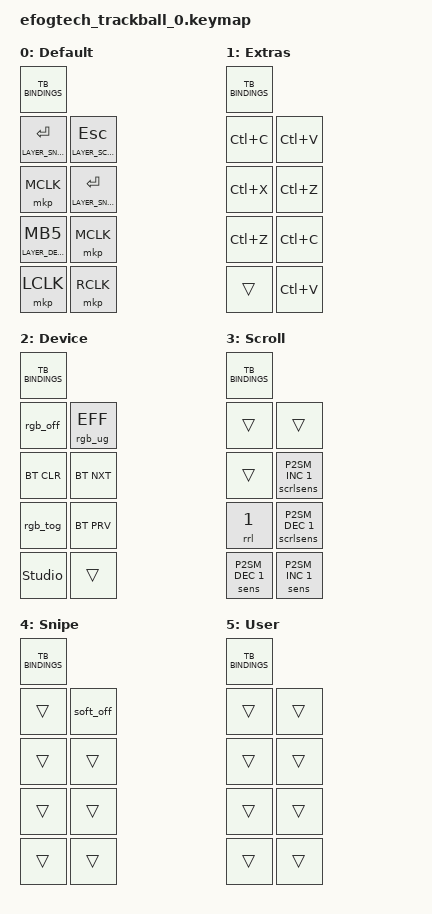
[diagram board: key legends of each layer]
#define ZMK_POINTING_DEFAULT_SCRL_VAL 30 /* faster default scroll speed */
#include <behaviors.dtsi>
#include <dt-bindings/zmk/bt.h>
#include <dt-bindings/zmk/keys.h>
#include <dt-bindings/zmk/pointing.h>
#include <dt-bindings/zmk/outputs.h>
#include <dt-bindings/zmk/p2sm.h>
#include <dt-bindings/zmk/rgb.h>
#include <dt-bindings/zmk/ext_power.h>
#include <behaviors/p2sm_behaviors.dtsi>
#include <behaviors/rate_limit.dtsi>
#include <behaviors/auto_hold.dtsi>

#ifndef CONFIG_EFOG_SCROLL_STEP
#define CONFIG_EFOG_SCROLL_STEP 10
#endif
#ifndef CONFIG_EFOG_SCROLL_MIN_STEP
#define CONFIG_EFOG_SCROLL_MIN_STEP 2
#endif
#ifndef CONFIG_EFOG_SCROLL_MAX_STEP
#define CONFIG_EFOG_SCROLL_MAX_STEP 12
#endif
#ifndef CONFIG_EFOG_SCROLL_TOGGLE_STEP
#define CONFIG_EFOG_SCROLL_TOGGLE_STEP 30
#endif
#ifndef CONFIG_EFOG_SCROLL_TOGGLE_MIN
#define CONFIG_EFOG_SCROLL_TOGGLE_MIN 1
#endif
#ifndef CONFIG_EFOG_SCROLL_TOGGLE_MAX
#define CONFIG_EFOG_SCROLL_TOGGLE_MAX 2
#endif

#define LAYER_DEFAULT 0
#define LAYER_EXTRAS 1
#define LAYER_DEVICE 2
#define LAYER_SCROLL 3
#define LAYER_SNIPE 4
#define LAYER_USER 5

#define SCROLL_MULTIPLIER 1
#define SCROLL_DIVISOR 3

#define SNIPE_MULTIPLIER 1
#define SNIPE_DIVISOR 4

#ifdef CONFIG_EFOG_TRACKBALL_POINTER_FLIPPED
/* Rotate the 2x4 key matrix when the board is mounted upside down. */
#define TB_BINDINGS( \
		r0c0, r0c1, \
		r1c0, r1c1, \
		r2c0, r2c1, \
		r3c0, r3c1) \
	r3c1 r3c0 \
	r2c1 r2c0 \
	r1c1 r1c0 \
	r0c1 r0c0
#else
#define TB_BINDINGS( \
		r0c0, r0c1, \
		r1c0, r1c1, \
		r2c0, r2c1, \
		r3c0, r3c1) \
	r0c0 r0c1 \
	r1c0 r1c1 \
	r2c0 r2c1 \
	r3c0 r3c1
#endif

/ {
	keymap {
		compatible = "zmk,keymap";

		default_layer {
			display-name = "Default";
			sensor-bindings = <&inc_dec_kp C_VOL_DN C_VOL_UP &inc_dec_kp LC(TAB) LC(LS(TAB))>;
			bindings = <
				TB_BINDINGS(
					&ltmkp LAYER_SNIPE ENTER,  &ltmkp LAYER_SCROLL ESC,
					&mkp MCLK,                &ltmkp LAYER_SNIPE ENTER,
					&ltm LAYER_DEVICE MB5,    &mkp MCLK, 
					&mkp LCLK,                &mkp RCLK
				)
			>;
		};

		layer2 {
			display-name = "Extras";
			sensor-bindings = <&inc_dec_kp C_VOL_DN C_VOL_UP &inc_dec_kp LC(TAB) LC(LS(TAB))>;
			bindings = <
				TB_BINDINGS(
					&kp LC(C),   &kp LC(V),
					&kp LC(X),   &kp LC(Z),
					&kp LC(Z),   &kp LC(C),
					&trans,      &kp LC(V)
				)
			>;
		};

		layer3 {
			display-name = "Device";
			sensor-bindings = <&inc_dec_kp C_VOL_DN C_VOL_UP &inc_dec_kp LC(TAB) LC(LS(TAB))>;
			bindings = <
				TB_BINDINGS(
					&rgb_off,           &rgb_ug RGB_EFF,
					&bt BT_CLR,         &bt BT_NXT,
					&rgb_tog,           &bt BT_PRV,
					&studio_unlock,     &trans
				)
			>;
		};

		layer4 {
			display-name = "Scroll";
			sensor-bindings = <&rotenc_sens P2SM_DEC P2SM_INC &rotenc_scrlsens P2SM_INC P2SM_DEC>;
			bindings = <
				TB_BINDINGS(
					&trans,              &trans,
					&trans,              &scrlsens P2SM_INC 1,
					&rrl 1,              &scrlsens P2SM_DEC 1,
					&sens P2SM_DEC 1,    &sens P2SM_INC 1
				)
			>;
		};

		layer5 {
			display-name = "Snipe";
			sensor-bindings = <&inc_dec_kp RIGHT LEFT &inc_dec_kp RIGHT LEFT>;
			bindings = <
				TB_BINDINGS(
					&trans,           &soft_off,
					&trans,           &trans,
					&trans,           &trans,
					&trans,           &trans
				)
			>;
		};

		layer6 {
			display-name = "User";
			sensor-bindings = <&inc_dec_kp C_VOL_DN C_VOL_UP &inc_dec_kp LC(TAB) LC(LS(TAB))>;
			bindings = <
				TB_BINDINGS(
					&trans,        &trans,
					&trans,        &trans,
					&trans,        &trans,
					&trans,        &trans
				)
			>;
		};
	};

	trackball {
		scroll {
			layers = <LAYER_SCROLL>;
			input-processors = <&zip_xy_scaler SCROLL_MULTIPLIER SCROLL_DIVISOR>, <&zip_axis_clamper>,
							   <&zip_xy_to_scroll_mapper>, <&zip_scroll_transform INPUT_TRANSFORM_Y_INVERT>;
		};

		snipe {
			layers = <LAYER_SNIPE>;
			input-processors = <&zip_xy_scaler SNIPE_MULTIPLIER SNIPE_DIVISOR>;
		};
	};

	macros {
		rgb_tog: rgb_tog {
			compatible = "zmk,behavior-macro";
			#binding-cells = <0>;
			wait-ms = <20>;
			bindings
			= <&rgb_ug RGB_TOG>
			, <&ext_power EP_TOG>
			;
		};

		rgb_off: rgb_off {
			compatible = "zmk,behavior-macro";
			#binding-cells = <0>;
			wait-ms = <20>;
			bindings
			= <&ext_power EP_OFF>
			, <&rgb_ug RGB_OFF>
			;
		};
	};

	behaviors {
		rrl {
			values-ms = <8 6 4 2>;
			feedback-duration = <65>;
		};

		ltm: layer-tap-momentary {
			compatible = "zmk,behavior-hold-tap";
			display-name = "Hold/tap (layer/mouse key)";
			#binding-cells = <2>;
			flavor = "tap-preferred";
			tapping-term-ms = <250>;
			hold-while-undecided;
			bindings = <&mo>, <&mkp>;
		};

		ltmkp: layer-tap-momentary-key-press {
			compatible = "zmk,behavior-hold-tap";
			display-name = "Hold/tap (layer/keyboard key)";
			#binding-cells = <2>;
			flavor = "tap-preferred";
			tapping-term-ms = <250>;
			hold-while-undecided;
			bindings = <&mo>, <&kp>;
		};

		sens: p2sm_sensitivity {
			feedback-duration = <65>;
			step = <50>;
			max-step = <8>;
		};

		scrlsens: p2sm_scroll_sensitivity {
			feedback-duration = <65>;
			step = <CONFIG_EFOG_SCROLL_STEP>;
			min-step = <CONFIG_EFOG_SCROLL_MIN_STEP>;
			max-step = <CONFIG_EFOG_SCROLL_MAX_STEP>;
		};

		scrlsenstog: p2sm_sens_toggle {
			display-name = "Scroll sensitivity (toggle 3%/6%)";
			feedback-duration = <65>;
			step = <CONFIG_EFOG_SCROLL_TOGGLE_STEP>;
			min-step = <CONFIG_EFOG_SCROLL_TOGGLE_MIN>;
			max-step = <CONFIG_EFOG_SCROLL_TOGGLE_MAX>;
			scroll;
		};

		sens_nowrap: sens_nowrap {
			compatible = "zmk,behavior-p2sm-sens";
			#binding-cells = <2>;
			feedback-duration = <65>;
			feedback-gpios = <&gpio0 24 GPIO_ACTIVE_HIGH>;
			feedback-extra-gpios = <&gpio1 0 GPIO_ACTIVE_HIGH>;
			step = <50>;
			min-step = <1>;
			max-step = <8>;
		};

		scrlsens_nowrap: scrlsens_nowrap {
			compatible = "zmk,behavior-p2sm-sens";
			#binding-cells = <2>;
			feedback-duration = <65>;
			feedback-gpios = <&gpio0 24 GPIO_ACTIVE_HIGH>;
			feedback-extra-gpios = <&gpio1 0 GPIO_ACTIVE_HIGH>;
			step = <CONFIG_EFOG_SCROLL_STEP>;
			min-step = <CONFIG_EFOG_SCROLL_MIN_STEP>;
			max-step = <CONFIG_EFOG_SCROLL_MAX_STEP>;
			scroll;
		};

		rotenc_sens: rotenc_sens {
			compatible = "zmk,behavior-sensor-rotate-var";
			#sensor-binding-cells = <2>;
			bindings = <&sens_nowrap>, <&sens_nowrap>;
		};

		rotenc_scrlsens: rotenc_scrlsens {
			compatible = "zmk,behavior-sensor-rotate-var";
			#sensor-binding-cells = <2>;
			bindings = <&scrlsens_nowrap>, <&scrlsens_nowrap>;
		};
	};
};
